AUTOSAR XML (schema 4-0-3)
standard types defined: Boolean, UInt32
package /AUTOSAR_Platform/DataConstrs
  range DC_Boolean: raw 0..1
package /PATAC/MSM/ComponentTypes
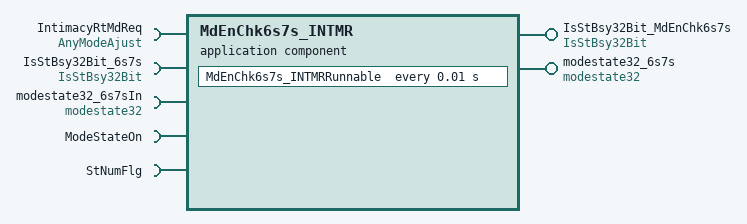
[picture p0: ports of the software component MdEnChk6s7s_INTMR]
  application sw component type MdEnChk6s7s_INTMR
    provide port IsStBsy32Bit_MdEnChk6s7s: nonqueued-sender-com-spec{data-element=IsStBsy32Bit/Val, init-value=0}, provided-interface=IsStBsy32Bit
    provide port modestate32_6s7s: nonqueued-sender-com-spec{data-element=modestate32/Val, init-value=0}, provided-interface=modestate32
    5 x require port:
      IntimacyRtMdReq: nonqueued-receiver-com-spec{data-element=AnyModeAjust/Val, filter=data-filter-type=ALWAYS, init-value=0}, required-interface=AnyModeAjust
      IsStBsy32Bit_6s7s: nonqueued-receiver-com-spec{data-element=IsStBsy32Bit/Val, filter=data-filter-type=ALWAYS, init-value=0}, required-interface=IsStBsy32Bit
      modestate32_6s7sIn: nonqueued-receiver-com-spec{data-element=modestate32/Val, filter=data-filter-type=ALWAYS, init-value=0}, required-interface=modestate32
      ModeStateOn: nonqueued-receiver-com-spec{data-element=ModeStateOn/Val, filter=data-filter-type=ALWAYS, init-value=0}, required-interface=ModeStateOn
      StNumFlg: required-interface=StNumFlg
        required-com-specs:
          data-element=Is4s, filter=data-filter-type=ALWAYS, init-value=0
          data-element=Is6s, filter=data-filter-type=ALWAYS, init-value=0
          data-element=Is6s7s, filter=data-filter-type=ALWAYS, init-value=0
          data-element=Is7s, filter=data-filter-type=ALWAYS, init-value=0
    behavior MdEnChk6s7s_INTMR_InternalBehavior
      timing event TMT_MdEnChk4sRunnable: start-on-event=MdEnChk6s7s_INTMRRunnable, period=0.01
      runnable MdEnChk6s7s_INTMRRunnable
        data-receive-point-by-arguments:
          7 x access:
            REC_IntimacyRtMdReq_Val: accessed-variable=IntimacyRtMdReq.Val
            REC_IsStBsy32Bit_6s7s_Val: accessed-variable=IsStBsy32Bit_6s7s.Val
            REC_modestate32_MdEnClearOut_Val: accessed-variable=modestate32_6s7sIn.Val
            REC_ModeStateOn_Val: accessed-variable=ModeStateOn.Val
            REC_StNumFlg_Is6s: accessed-variable=StNumFlg.Is6s
            REC_StNumFlg_Is6s7s: accessed-variable=StNumFlg.Is6s7s
            REC_StNumFlg_Is7s: accessed-variable=StNumFlg.Is7s
        data-send-points:
          access SEND_IsStBsy32Bit_MdEnChk6s7s_Val: accessed-variable=IsStBsy32Bit_MdEnChk6s7s.Val
          access SEND_modestate32_6s7s_Val: accessed-variable=modestate32_6s7s.Val
  swc implementation MdEnChk6s7s_INTMR_Implementation: behavior=MdEnChk6s7s_INTMR_InternalBehavior
    code-descriptors:
      code Default: artifact-descriptors=autosar-engineering-object={short-label=Default, category=SWSRC}
package /PATAC/MSM/ModeAdjust/PortInterface
  5 x sender receiver interface:
    AnyModeAjust: invalidation-policy{data-element=AnyModeAjust/Val, handle-invalid=DONT-INVALIDATE}
      data Val: type=Boolean
    IsStBsy32Bit: invalidation-policy{data-element=IsStBsy32Bit/Val, handle-invalid=DONT-INVALIDATE}
      data Val: type=UInt32
    modestate32: invalidation-policy{data-element=modestate32/Val, handle-invalid=DONT-INVALIDATE}
      data Val: type=UInt32
    ModeStateOn: invalidation-policy{data-element=ModeStateOn/Val, handle-invalid=DONT-INVALIDATE}
      data Val: type=Boolean
    StNumFlg
      4 x data, all with type=Boolean:
        Is4s
        Is6s
        Is6s7s
        Is7s
      invalidation-policys:
        data-element=Is7s, handle-invalid=DONT-INVALIDATE
        data-element=Is6s, handle-invalid=DONT-INVALIDATE
        data-element=Is4s, handle-invalid=DONT-INVALIDATE
        data-element=Is6s7s, handle-invalid=DONT-INVALIDATE
